# SC32F10T_10G register map
File version: 1.0
CPU: CM0+ r0p1, little endian, MPU, no FPU, 4 interrupt priority bits
Registers are 32-bit, read-write, reset 0x0 unless marked. A register's access mark holds for its fields unless they carry their own. Offsets are from the block's base; [hi:lo] are bit positions; {n}, {i} and the like mark numbered series.

## WDT
Base 0x40000330
0x0C WDTCON — WDT控制寄存器
  [0] CLRWDT — WDT计数清零位该位通过软件写1，由硬件自动清0。0：无影响1： WDT计数器从0开始计数
0x10 WDTCFG — WDT设置寄存器
  [3:0] WDTCKS — 看门狗时钟选择：WDTCKS[2:0]WDT溢出时间000500ms001250ms010125ms01162.5ms10031.5ms10115.75ms1107.88ms1113.94ms

## BTM
Base 0x40022100
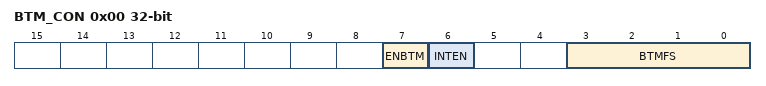
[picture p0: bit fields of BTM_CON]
0x00 BTM_CON — 低频定时器控制寄存器
  [7] ENBTM — Base Timer启动控制位 0：Base Timer不启动 1：Base Timer启动
  [6] INTEN — 中断请求 CPU的使能控制位 0：禁止中断请求 1：使能中断请求
  [3:0] BTMFS — 低频时钟中断频率选择 0000：每15.625ms产生一个中断 0001：每31.25ms产生一个中断 0010：每62.5ms产生一个中断 0011：每125ms产生一个中断 0100：每0.25 s产生一个中断 0101：每0.5 s产生一个中断 0110：每1.0 s产生一个中断 0111：每2.0 s产生一个中断 1000：每4.0 s产生一个中断 1001：每8.0 s产生一个中断 10
0x04 BTM_STS — BTM标志位寄存器
  [0] BTMIF — Base Timer中断标志位该位由硬件置1，通过软件写1清0。BTM计数满足BTMFS设置条件时该位自动置起。

## CRC
Base 0x40002000
0x00 CRC_DR — CRC数据寄存器
  [31:0] CRCDR — CRC数据寄存器位该寄存器用于向 CRC 计算器写入新数据。读取寄存器时可读出之前的 CRC 计算结果。如果数据大小小于 32 位，则最低有效位可用于写入 / 读取正确值。该寄存器的操作要求如下：首先必须对CRC_CON.CRCRST写1，将CRCDR复位当CRCREG被写入时，硬件自动计算CRC结果，并继续存放于CRCDR内当需要时，即时读出CRC计算结果。
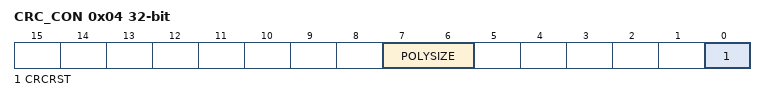
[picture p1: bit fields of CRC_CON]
0x04 CRC_CON — CRC控制寄存器
  [7:6] POLYSIZE — CRC多项式大小设置位00：32 位多项式01：16 位多项式10：8 位多项式11：7 位多项式
  [0] CRCRST — CRCDR寄存器复位(Q31~Q0)该位通过软件写1，由硬件自动清0。0：无影响1：复位CRCDR，复位的值为用户写入CRC_INIT 寄存器的值
0x08 CRC_INT — CRC初始值寄存器
  [31:0] CRC_INIT — 可编程 CRC 初始值，复位值：0xFFFF FFFF此寄存器用于写入 CRC 初始值
0x0C CRC_POL — CRC多项式设置寄存器
  [31:0] POL — 可编程多项式，复位值：0x04C1_1DB7此寄存器用于写入要用于 CRC 计算的多项式系数 如果多项式大小小于 32 位，则必须使用最低有效位编程正确值。

## PWM0
Base 0x40020200
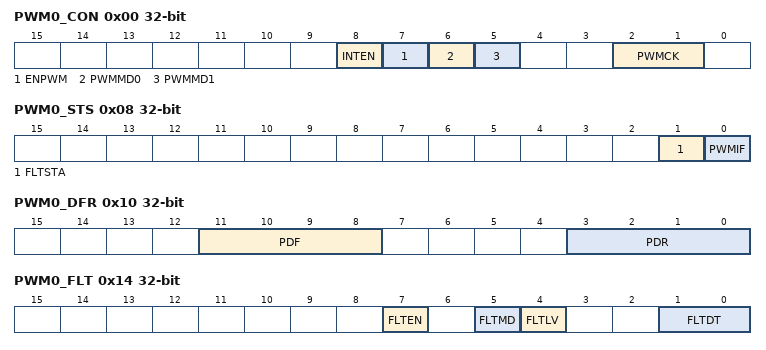
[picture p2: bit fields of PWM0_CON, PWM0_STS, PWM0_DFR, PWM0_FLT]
0x00 PWM0_CON — PWM0控制寄存器
  [8] INTEN — 中断请求 CPU 的使能控制位0：禁止中断请求1：使能中断请求
  [7] ENPWM — PWM模块开关控制位1：允许Clock进到 PWM 单元，PWM处于工作状态，PWM输出口的状态由寄存器ENPWMx控制（x=0~7）0：PWM单元停止工作，PWM计数器清0，全部 PWM输出口设置为GPIO状态
  [6] PWMMD0 — PWM波形对齐模式选择位0：边沿对齐模式1：中心对齐模式
  [5] PWMMD1 — PWM波形互补模式设置位0：独立模式1：互补模式
  [2:1] PWMCK — PWM时钟频率档位控制位用于设定PWM时钟频率fPWM0000：fPCLK0/1001：fPCLK0/2010：fPCLK0/4011：fPCLK0/8100：fPCLK0/16101：fPCLK0/32110：fPCLK0/64111：fPCLK0/128
0x04 PWM0_CHN — PWM0通道设置寄存器
  [7:0] ENPWMx(x — PWM0x波形输出选择0：PWM0x输出被关闭并作为GPIO1：当ENPWM=1时，PWM0x所在的管脚作为波形输出口说明：如果ENPWM置1，PWM模块被打开，但ENPWMx=0，PWM输出被关闭并作为GPIO口。此时PWM模块可以作为一个16位Timer使用，若此时PWM0_CON.INTEN = 1，PWM仍然会产生中断。
0x08 PWM0_STS — PWM0状态标志寄存器
  [1] FLTSTA — PWM故障检测状态标志位0：PWM处于正常输出状态；1：故障检测有效，PWM输出处于高阻状态，如果处于锁存模式，此位可软件清0
  [0] PWMIF — PWM中断请求标志位该位由硬件置1，通过软件写1清0。当PWM 计数器溢出时(即：计数值超过 PWMPD)，该位由硬件置1。如果此时PWM0_CON.INTEN = 1，将产生 PWM0 中断 。
0x0C PWM0_INV — PWM0波形输出反向控制寄存器
  [1] INVx(x — PWM0x波形输出反向控制1：PWM0x波形输出反向0：PWM0x波形输出不反向
0x10 PWM0_DFR — PWM0死区设置寄存器
  [11:8] PDF — 下降沿死区时间设置位此位仅在互补模式设置有效：PWM下降沿死区时间= 4*PDF[3:0] / fPCLK
  [3:0] PDR — 上升沿死区时间设置位此位仅在互补模式设置有效：PWM 上升沿死区时间= 4*PDR[3:0] / fPCLK
0x14 PWM0_FLT — PWM0故障检测设置寄存器
  [7] FLTEN — PWM故障检测功能控制位0：故障检测功能关闭1：故障检测功能开启
  [5] FLTMD — PWM故障检测模式设置位0：锁存模式，当故障输入有效时，故障检测状态标志位FLTSTA由硬件置1，PWM停止输出，当故障输入无效时FLTSTA状态不变1：立即模式：当故障输入有效时，故障检测状态标志位FLTSTA由硬件置1，PWM停止输出，当故障输入无效时FLTSTA状态立刻被硬件清0，PWM波形将在PWM计数器计数到0时恢复输出
  [4] FLTLV — PWM故障检测电平选择位0：故障检测低电平有效1：故障检测高电平有效
  [1:0] FLTDT — PWM故障检测输入信号滤波时间设置00：滤波时间为001：滤波时间为1us10：滤波时间为4us11：滤波时间为16us
0x18 PWM0_CYCLE — PWM0周期寄存器
  [15:0] PWMPD — PWM0周期设置位此数值代表 PWM输出波形的 (周期 – 1); 即PWM输出的周期值为（PWMPD[15:0] + 1 ）* fPWM0；

## PWM0_DTx — PWM0_DTx（x = 0~7）
Base 0x40020230
{0x0+4i} PWM0_DT{i} (i=0..7) — PWM0通道{i} duty寄存器
  [15:0] PDT — PWM0x波形占空比长度设置，x = 0~7独立模式：PWM0x的波形的高电平宽度是PDTx [15:0]个PWM时钟；互补模式：互补通道PWM0x和PWM0y，y=x+1, PWM0x和PWM0y的波形的高电平宽度是PDTx [15:0]个PWM时钟。

## LEDPWM
Base 0x40022300
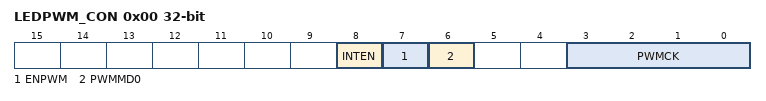
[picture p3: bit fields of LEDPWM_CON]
0x00 LEDPWM_CON — LEDPWM控制寄存器
  [8] INTEN — 中断请求 CPU 的使能控制位0：禁止中断请求1：使能中断请求
  [7] ENPWM — PWM模块开关控制位 1：允许Clock进到 PWM 单元，PWM处于工作状态，PWM输出口的状态由寄存器ENPWMx控制（x=0~7） 0：PWM单元停止工作，PWM计数器清零，全部 PWM输出口设置为GPIO状态
  [6] PWMMD0 — PWM波形对齐模式选择位0：边沿对齐模式 1：中心对齐模式
  [3:0] PWMCK — PWM时钟频率档位控制位用于设定LEDPWM时钟频率fLEDPWM000：fPCLK2/1001：fPCLK2/2010：fPCLK2/4011：fPCLK2/8100：fPCLK2/16101：fPCLK2/32110：fPCLK2/64111：fPCLK2/128
0x04 LEDPWM_CHN — LEDPWM通道设置寄存器
  [31:0] ENPWMxx — LEDPWMx波形输出选择0：LEDPWMx输出被关闭并作为GPIO1：当ENPWM=1时，LEDPWMx所在的管脚作为波形输出口说明：如果ENPWM置1，PWM模块被打开，但ENPWMx=0，PWM输出被关闭并作为GPIO口。此时PWM模块可以作为一个16位Timer使用，若此时LEDPWM_CON.INTEN =1，PWM仍然会产生中断。
0x08 LEDPWM_STS — LEDPWM状态标志寄存器
  [0] PWMIF — LEDPWM中断请求标志位该位由硬件置1，通过软件写1清0。当PWM 计数器溢出时(即: 计数值超过 PWMPD时)，该位由硬件置1 。如果此时LEDPWM.INTEN = 1，将产生 LEDPWM 中断 。
0x0C LEDPWM_INV — LEDPWM波形输出反向控制寄存器
  [31:0] INVxX — LEDPWMx波形输出反向控制1：LEDPWMx波形输出反向0：LEDPWMx波形输出不反向
0x18 LEDPWM_CYCLE — LEDPWM周期寄存器
  [7:0] PWMPD — LEDPWM周期设置位此数值代表 PWM输出波形的 (周期–1); 即PWM输出的周期值为（PWMPD[7:0] + 1 ）* fLEDPWM ;
